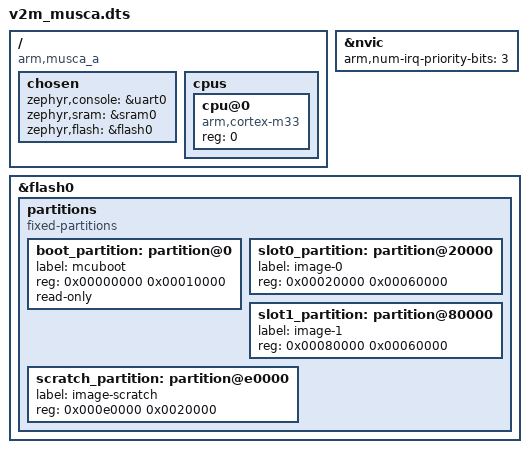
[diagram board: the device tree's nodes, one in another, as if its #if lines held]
/dts-v1/;

#include <arm/armv8-m.dtsi>
#include <dt-bindings/i2c/i2c.h>

/ {
	compatible = "arm,musca_a";
	#address-cells = <1>;
	#size-cells = <1>;

	chosen {
		zephyr,console = &uart0;
		zephyr,sram = &sram0;
		zephyr,flash = &flash0;
	};

	cpus {
		#address-cells = <1>;
		#size-cells = <0>;

		cpu@0 {
			device_type = "cpu";
			compatible = "arm,cortex-m33";
			reg = <0>;
		};
	};

};

&nvic {
	arm,num-irq-priority-bits = <3>;
};

#if defined (CONFIG_ARM_SECURE_FIRMWARE)
#include <arm/v2m_musca-secure.dtsi>
#else
#include <arm/v2m_musca-nonsecure.dtsi>
#endif

/* flash0 is the simulated flash device that code runs from. */
&flash0 {
	partitions {
		compatible = "fixed-partitions";
		#address-cells = <1>;
		#size-cells = <1>;

		boot_partition: partition@0 {
			label = "mcuboot";
			reg = <0x00000000 0x00010000>;
			read-only;
		};

		slot0_partition: partition@20000 {
			label = "image-0";
			reg = <0x00020000 0x00060000>;
		};
		slot1_partition: partition@80000 {
			label = "image-1";
			reg = <0x00080000 0x00060000>;
		};
		scratch_partition: partition@e0000 {
			label = "image-scratch";
			reg = <0x000e0000 0x0020000>;
		};
	};
};
